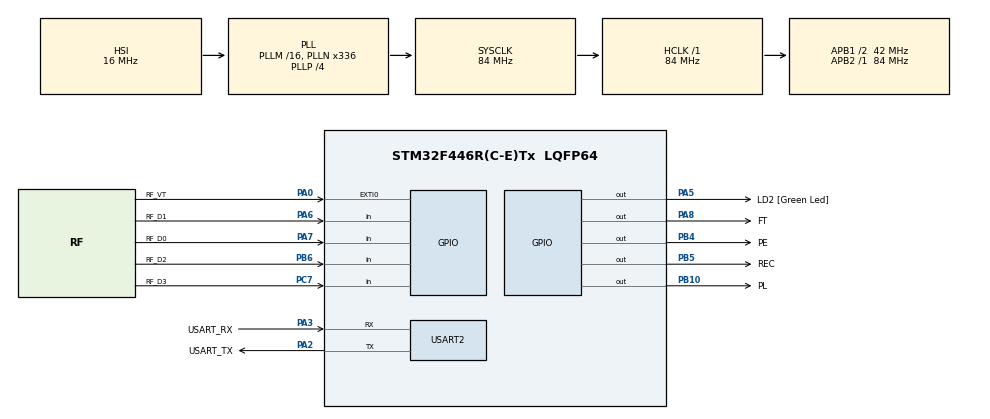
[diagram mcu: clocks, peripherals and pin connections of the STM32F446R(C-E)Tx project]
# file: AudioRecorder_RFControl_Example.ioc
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Mcu.Family=STM32F4
PH0-OSC_IN.Signal=RCC_OSC_IN
RCC.CortexFreq_Value=84000000
PA14.GPIO_Label=TCK
PA6.GPIO_Label=RF_D1
PB6.GPIO_Label=RF_D2
RCC.SYSCLKSource=RCC_SYSCLKSOURCE_PLLCLK
ProjectManager.StackSize=0x400
RCC.HCLKFreq_Value=84000000
RCC.APB2TimFreq_Value=84000000
PB6.Signal=GPIO_Input
PC7.Signal=GPIO_Input
RCC.AHBFreq_Value=84000000
PH0-OSC_IN.Mode=HSE-External-Oscillator
RCC.HSE_VALUE=8000000
PC14-OSC32_IN.Mode=LSE-External-Oscillator
PA14.Mode=Serial_Wire
PA8.Signal=GPIO_Output
RCC.FLatency-AdvancedSettings=FLASH_LATENCY_2
PH1-OSC_OUT.Mode=HSE-External-Oscillator
Mcu.Package=LQFP64
PA6.Signal=GPIO_Input
USART2.VirtualMode=VM_ASYNC
PA2.GPIO_Label=USART_TX
PB5.GPIO_Label=REC
RCC.APB1TimFreq_Value=84000000
PB4.Signal=GPIO_Output
PA3.Signal=USART2_RX
PB3.GPIO_Label=SWO
PC15-OSC32_OUT.Mode=LSE-External-Oscillator
RCC.APB1CLKDivider=RCC_HCLK_DIV2
PC14-OSC32_IN.Signal=RCC_OSC32_IN
PA0-WKUP.GPIO_Label=RF_VT
PA0-WKUP.Signal=GPXTI0
PA3.Mode=Asynchronous
PA13.Signal=SYS_JTMS-SWDIO
PA8.GPIO_Label=FT
ProjectManager.TargetToolchain=STM32CubeIDE
PB10.GPIO_Label=PL
RCC.USBFreq_Value=168000000
PC15-OSC32_OUT.Signal=RCC_OSC32_OUT
PB10.Signal=GPIO_Output
PA5.Signal=GPIO_Output
board=NUCLEO-F446RE
RCC.VCOOutputFreq_Value=336000000
RCC.APB2Freq_Value=84000000
PB4.GPIO_Label=PE
PH1-OSC_OUT.Signal=RCC_OSC_OUT
PA13.Mode=Serial_Wire
Mcu.Name=STM32F446R(C-E)Tx
PA13.GPIO_Label=TMS
PA2.Signal=USART2_TX
PC7.GPIO_Label=RF_D3
RCC.48MHZClocksFreq_Value=84000000
PB3.Signal=SYS_JTDO-SWO
NVIC.EXTI0_IRQn=true\:0\:0\:false\:false\:true\:true\:true
RCC.SYSCLKFreq_VALUE=84000000
PB5.Signal=GPIO_Output
PA7.GPIO_Label=RF_D0
PA5.GPIO_Label=LD2 [Green Led]
PA14.Signal=SYS_JTCK-SWCLK
ProjectManager.HeapSize=0x200
RCC.HSI_VALUE=16000000
RCC.PLLP=RCC_PLLP_DIV4
NVIC.PriorityGroup=NVIC_PRIORITYGROUP_0
RCC.PLLN=336
PA2.Mode=Asynchronous
RCC.APB1Freq_Value=42000000
PA3.GPIO_Label=USART_RX
PA7.Signal=GPIO_Input

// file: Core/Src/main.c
/* USER CODE BEGIN Header */
/**
  ******************************************************************************
  * @file           : main.c
  * @brief          : Main program body
  ******************************************************************************
  * @attention
  *
  * <h2><center>&copy; Copyright (c) 2022 STMicroelectronics.
  * All rights reserved.</center></h2>
  *
  * This software component is licensed by ST under BSD 3-Clause license,
  * the "License"; You may not use this file except in compliance with the
  * License. You may obtain a copy of the License at:
  *                        opensource.org/licenses/BSD-3-Clause
  *
  ******************************************************************************
  */
/* USER CODE END Header */
#include "main.h"

/* USER CODE BEGIN Includes */
#include "isd1820.h"
/* USER CODE END Includes */

UART_HandleTypeDef huart2;

void SystemClock_Config(void);
static void MX_GPIO_Init(void);
static void MX_USART2_UART_Init(void);

/* USER CODE BEGIN 0 */
uint8_t state = 0;
/* USER CODE END 0 */

int main(void)
{

  /* MCU Configuration--------------------------------------------------------*/

  /* Reset of all peripherals, Initializes the Flash interface and the Systick. */
  HAL_Init();

  /* Configure the system clock */
  SystemClock_Config();

  /* Initialize all configured peripherals */
  MX_GPIO_Init();
  MX_USART2_UART_Init();
  /* USER CODE BEGIN 2 */
  ///ISD1820_RecordAndPlay(10000, 5000);
  /* USER CODE END 2 */

  /* Infinite loop */
  while (1)
  {
	  switch (state) {
	  	case 0:
	  		HAL_GPIO_WritePin(LD2_GPIO_Port, LD2_Pin, 0); //turn LED off
	  		break;

		case 1://button A
			ISD1820_RecordAndPlay(10000, 8000); //records 10 seconds and plays 8 seconds
			state = 0;
			break;
		case 2://button B
			ISD1820_Play(5000); //play 5 seconds
			state = 0;
			break;
		case 3://button C
			ISD1820_Record(10000);
			state = 0;
			break;
		case 4://button D
			ISD1820_PlayComplete();
			state = 0;
			break;
		default:
			break;
	}
  }
}

void SystemClock_Config(void)
{
  RCC_OscInitTypeDef RCC_OscInitStruct = {0};
  RCC_ClkInitTypeDef RCC_ClkInitStruct = {0};

  /** Configure the main internal regulator output voltage
  */
  __HAL_RCC_PWR_CLK_ENABLE();
  __HAL_PWR_VOLTAGESCALING_CONFIG(PWR_REGULATOR_VOLTAGE_SCALE3);
  /** Initializes the RCC Oscillators according to the specified parameters
  * in the RCC_OscInitTypeDef structure.
  */
  RCC_OscInitStruct.OscillatorType = RCC_OSCILLATORTYPE_HSI;
  RCC_OscInitStruct.HSIState = RCC_HSI_ON;
  RCC_OscInitStruct.HSICalibrationValue = RCC_HSICALIBRATION_DEFAULT;
  RCC_OscInitStruct.PLL.PLLState = RCC_PLL_ON;
  RCC_OscInitStruct.PLL.PLLSource = RCC_PLLSOURCE_HSI;
  RCC_OscInitStruct.PLL.PLLM = 16;
  RCC_OscInitStruct.PLL.PLLN = 336;
  RCC_OscInitStruct.PLL.PLLP = RCC_PLLP_DIV4;
  RCC_OscInitStruct.PLL.PLLQ = 2;
  RCC_OscInitStruct.PLL.PLLR = 2;
  if (HAL_RCC_OscConfig(&RCC_OscInitStruct) != HAL_OK)
  {
    Error_Handler();
  }
  /** Initializes the CPU, AHB and APB buses clocks
  */
  RCC_ClkInitStruct.ClockType = RCC_CLOCKTYPE_HCLK|RCC_CLOCKTYPE_SYSCLK
                              |RCC_CLOCKTYPE_PCLK1|RCC_CLOCKTYPE_PCLK2;
  RCC_ClkInitStruct.SYSCLKSource = RCC_SYSCLKSOURCE_PLLCLK;
  RCC_ClkInitStruct.AHBCLKDivider = RCC_SYSCLK_DIV1;
  RCC_ClkInitStruct.APB1CLKDivider = RCC_HCLK_DIV2;
  RCC_ClkInitStruct.APB2CLKDivider = RCC_HCLK_DIV1;

  if (HAL_RCC_ClockConfig(&RCC_ClkInitStruct, FLASH_LATENCY_2) != HAL_OK)
  {
    Error_Handler();
  }
}

static void MX_USART2_UART_Init(void)
{

  huart2.Instance = USART2;
  huart2.Init.BaudRate = 115200;
  huart2.Init.WordLength = UART_WORDLENGTH_8B;
  huart2.Init.StopBits = UART_STOPBITS_1;
  huart2.Init.Parity = UART_PARITY_NONE;
  huart2.Init.Mode = UART_MODE_TX_RX;
  huart2.Init.HwFlowCtl = UART_HWCONTROL_NONE;
  huart2.Init.OverSampling = UART_OVERSAMPLING_16;
  if (HAL_UART_Init(&huart2) != HAL_OK)
  {
    Error_Handler();
  }

}

static void MX_GPIO_Init(void)
{
  GPIO_InitTypeDef GPIO_InitStruct = {0};

  /* GPIO Ports Clock Enable */
  __HAL_RCC_GPIOC_CLK_ENABLE();
  __HAL_RCC_GPIOH_CLK_ENABLE();
  __HAL_RCC_GPIOA_CLK_ENABLE();
  __HAL_RCC_GPIOB_CLK_ENABLE();

  /*Configure GPIO pin Output Level */
  HAL_GPIO_WritePin(GPIOA, LD2_Pin|FT_Pin, GPIO_PIN_RESET);

  /*Configure GPIO pin Output Level */
  HAL_GPIO_WritePin(GPIOB, PL_Pin|PE_Pin|REC_Pin, GPIO_PIN_RESET);

  /*Configure GPIO pin : RF_VT_Pin */
  GPIO_InitStruct.Pin = RF_VT_Pin;
  GPIO_InitStruct.Mode = GPIO_MODE_IT_RISING;
  GPIO_InitStruct.Pull = GPIO_NOPULL;
  HAL_GPIO_Init(RF_VT_GPIO_Port, &GPIO_InitStruct);

  /*Configure GPIO pins : LD2_Pin FT_Pin */
  GPIO_InitStruct.Pin = LD2_Pin|FT_Pin;
  GPIO_InitStruct.Mode = GPIO_MODE_OUTPUT_PP;
  GPIO_InitStruct.Pull = GPIO_NOPULL;
  GPIO_InitStruct.Speed = GPIO_SPEED_FREQ_LOW;
  HAL_GPIO_Init(GPIOA, &GPIO_InitStruct);

  /*Configure GPIO pins : RF_D1_Pin RF_D0_Pin */
  GPIO_InitStruct.Pin = RF_D1_Pin|RF_D0_Pin;
  GPIO_InitStruct.Mode = GPIO_MODE_INPUT;
  GPIO_InitStruct.Pull = GPIO_NOPULL;
  HAL_GPIO_Init(GPIOA, &GPIO_InitStruct);

  /*Configure GPIO pins : PL_Pin PE_Pin REC_Pin */
  GPIO_InitStruct.Pin = PL_Pin|PE_Pin|REC_Pin;
  GPIO_InitStruct.Mode = GPIO_MODE_OUTPUT_PP;
  GPIO_InitStruct.Pull = GPIO_NOPULL;
  GPIO_InitStruct.Speed = GPIO_SPEED_FREQ_LOW;
  HAL_GPIO_Init(GPIOB, &GPIO_InitStruct);

  /*Configure GPIO pin : RF_D3_Pin */
  GPIO_InitStruct.Pin = RF_D3_Pin;
  GPIO_InitStruct.Mode = GPIO_MODE_INPUT;
  GPIO_InitStruct.Pull = GPIO_NOPULL;
  HAL_GPIO_Init(RF_D3_GPIO_Port, &GPIO_InitStruct);

  /*Configure GPIO pin : RF_D2_Pin */
  GPIO_InitStruct.Pin = RF_D2_Pin;
  GPIO_InitStruct.Mode = GPIO_MODE_INPUT;
  GPIO_InitStruct.Pull = GPIO_NOPULL;
  HAL_GPIO_Init(RF_D2_GPIO_Port, &GPIO_InitStruct);

  /* EXTI interrupt init*/
  HAL_NVIC_SetPriority(EXTI0_IRQn, 0, 0);
  HAL_NVIC_EnableIRQ(EXTI0_IRQn);

}

/* USER CODE BEGIN 4 */
void HAL_GPIO_EXTI_Callback(uint16_t GPIO_Pin){
	if (GPIO_Pin == RF_VT_Pin){
		HAL_GPIO_WritePin(LD2_GPIO_Port, LD2_Pin, 1); //turn LED on
		if(HAL_GPIO_ReadPin(RF_D3_GPIO_Port, RF_D3_Pin)){ //button C
			state = 3;
		}else if(HAL_GPIO_ReadPin(RF_D2_GPIO_Port, RF_D2_Pin)){ //button A
			state = 1;
		}else if(HAL_GPIO_ReadPin(RF_D1_GPIO_Port, RF_D1_Pin)){ //button D
			state = 4;
		}else{ //button B
			state = 2;
		}
	}
}
/* USER CODE END 4 */

void Error_Handler(void)
{
  __disable_irq();
  while (1)
  {
  }
}

/************************ (C) COPYRIGHT STMicroelectronics *****END OF FILE****/
